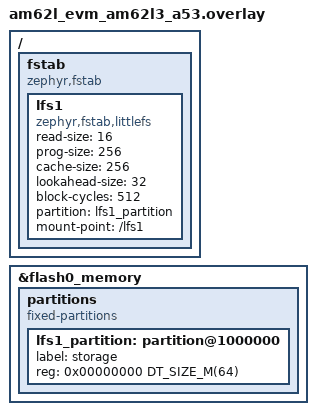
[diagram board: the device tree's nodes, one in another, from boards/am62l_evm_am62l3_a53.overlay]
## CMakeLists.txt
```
#
# Copyright (c) 2019 Peter Bigot Consulting, LLC
#
# SPDX-License-Identifier: Apache-2.0
#

cmake_minimum_required(VERSION 3.28.0)
find_package(Zephyr REQUIRED HINTS $ENV{ZEPHYR_BASE})
project(littlefs)

FILE(GLOB app_sources src/*.c)
target_sources(app PRIVATE ${app_sources})
```

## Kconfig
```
# Copyright (c) 2019 Peter Bigot Consulting, LLC
# SPDX-License-Identifier: Apache-2.0

mainmenu "littlefs sample"

config APP_WIPE_STORAGE
	bool "Option to clear the flash area before mounting"
	help
	  Use this to force an existing file system to be created.

choice
	prompt "Storage backend type used by the application"
	default APP_LITTLEFS_STORAGE_FLASH
	help
	  Specify the type of storage backend.

config APP_LITTLEFS_STORAGE_FLASH
	bool "Use flash memory backend"

config APP_LITTLEFS_STORAGE_BLK_SDMMC
	bool "Use block device (e.g. SD MMC) backend"

config APP_LITTLEFS_STORAGE_BLK_FTL
	bool "Use FTL (Flash Translation Layer) block device backend"
endchoice

source "Kconfig.zephyr"
```

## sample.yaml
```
sample:
  name: littlefs filesystem sample
common:
  tags:
    - filesystem
    - littefs
tests:
  sample.filesystem.littlefs:
    build_only: true
    platform_allow:
      - nrf52840dk/nrf52840
      - particle_xenon
      - disco_l475_iot1
      - mimxrt685_evk/mimxrt685s/cm33
      - mimxrt1060_evk/mimxrt1062/qspi
      - mimxrt1064_evk
      - qemu_x86
      - native_sim
      - mimxrt1160_evk/mimxrt1166/cm7
      - lpcxpresso55s69/lpc55s69/cpu0
      - mr_canhubk3
      - stm32f429i_disc1
      - stm32f746g_disco
      - stm32h747i_disco/stm32h747xx/m7
      - stm32h750b_dk
      - nrf54l15dk/nrf54l15/cpuapp
      - frdm_ke17z
      - frdm_ke17z512
      - s32z2xxdc2/s32z270/rtu0
      - s32z2xxdc2/s32z270/rtu1
      - s32z2xxdc2@D/s32z270/rtu0
      - s32z2xxdc2@D/s32z270/rtu1
      - s32k5xxcvb/s32k566/m7
      - s32k5xxcvb/s32k566/r52
    integration_platforms:
      - nrf52840dk/nrf52840
  sample.filesystem.littlefs.blk:
    build_only: true
    extra_args:
      - CONF_FILE=prj_blk.conf
    platform_allow:
      - rcar_h3ulcb/r8a77951/a57
      - rcar_salvator_xs
  sample.filesystem.littlefs.nrf52840dk_spi:
    build_only: true
    platform_allow: nrf52840dk/nrf52840
    extra_args:
      - EXTRA_CONF_FILE=boards/nrf52840dk_nrf52840_spi.conf
      - DTC_OVERLAY_FILE=boards/nrf52840dk_nrf52840_spi.overlay
  sample.filesystem.littlefs.nrf52840dk_qspi:
    build_only: true
    platform_allow: nrf52840dk/nrf52840
    extra_args:
      - EXTRA_CONF_FILE=boards/nrf52840dk_nrf52840_qspi.conf
      - DTC_OVERLAY_FILE=boards/nrf52840dk_nrf52840_qspi.overlay
  sample.filesystem.littlefs.stm32h747i_disco_m7_blk:
    build_only: true
    platform_allow: stm32h747i_disco/stm32h747xx/m7
    extra_args:
      - EXTRA_CONF_FILE=stm32_blk.conf
      - CONF_FILE=prj_blk.conf
    extra_configs:
      - CONFIG_SDMMC_STM32_HWFC=y
  sample.filesystem.littlefs.nucleo_h743zi_qspi:
    build_only: true
    platform_allow: nucleo_h743zi
    extra_args:
      - EXTRA_CONF_FILE=boards/nucleo_h743zi_qspi.conf
  sample.filesystem.littlefs.nucleo_h743zi_blk:
    build_only: true
    platform_allow: nucleo_h743zi
    extra_args:
      - EXTRA_CONF_FILE=boards/nucleo_h743zi_blk.conf
      - CONF_FILE=prj_blk.conf
  sample.filesystem.littlefs.stm32l562e_dk_ospi:
    build_only: true
    platform_allow: stm32l562e_dk
    extra_args:
      - EXTRA_CONF_FILE=boards/stm32l562e_dk_ospi.conf
  sample.filesystem.littlefs.stm32f746g_disco_blk:
    build_only: true
    platform_allow: stm32f746g_disco
    extra_args:
      - EXTRA_CONF_FILE=stm32_blk.conf
      - CONF_FILE=prj_blk.conf
    extra_configs:
      - CONFIG_SDMMC_STM32_HWFC=y
  sample.filesystem.littlefs.frdm_rw612_nand:
    build_only: true
    platform_allow: frdm_rw612
    extra_args:
      - EXTRA_CONF_FILE=boards/frdm_rw612_nand.conf
      - DTC_OVERLAY_FILE=boards/frdm_rw612_nand.overlay
```

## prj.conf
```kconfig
#
# Copyright (c) 2019 Peter Bigot Consulting, LLC
#
# SPDX-License-Identifier: Apache-2.0
#

# Optionally force the file system to be recreated
#CONFIG_APP_WIPE_STORAGE=y

# fs_dirent structures are big.
CONFIG_MAIN_STACK_SIZE=4096

# Let __ASSERT do its job
CONFIG_DEBUG=y

CONFIG_LOG=y
CONFIG_LOG_MODE_MINIMAL=y

CONFIG_FLASH=y
CONFIG_FLASH_MAP=y

CONFIG_FILE_SYSTEM=y
CONFIG_FILE_SYSTEM_LITTLEFS=y
```

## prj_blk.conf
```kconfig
#
# Copyright (c) 2022 Lukasz Majewski, DENX Software Engineering GmbH
#
# SPDX-License-Identifier: Apache-2.0
#

CONFIG_DISK_ACCESS=y
CONFIG_DISK_DRIVERS=y

CONFIG_DEBUG=y
CONFIG_LOG=y
CONFIG_LOG_MODE_MINIMAL=y

CONFIG_FILE_SYSTEM=y
CONFIG_FILE_SYSTEM_LITTLEFS=y

CONFIG_FS_LITTLEFS_BLK_DEV=y
CONFIG_FS_LITTLEFS_FMP_DEV=n
CONFIG_APP_LITTLEFS_STORAGE_BLK_SDMMC=y

CONFIG_NOCACHE_MEMORY=y
```

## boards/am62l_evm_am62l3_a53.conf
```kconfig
#
# SPDX-FileCopyrightText: 2026 Texas Instruments Incorporated
#
# SPDX-License-Identifier: Apache-2.0
#

CONFIG_MPU_ALLOW_FLASH_WRITE=y
```

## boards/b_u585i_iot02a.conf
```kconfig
#
# Copyright (c) 2023 OS Systems
#
# SPDX-License-Identifier: Apache-2.0
#

CONFIG_FS_LITTLEFS_FC_HEAP_SIZE=8192
```

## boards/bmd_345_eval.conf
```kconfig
#
# Copyright (c) 2021 Linumiz
#
# SPDX-License-Identifier: Apache-2.0

# Need this when storage is on flash
CONFIG_MPU_ALLOW_FLASH_WRITE=y

# Need this when storage is on MX25R64
CONFIG_NORDIC_QSPI_NOR_FLASH_LAYOUT_PAGE_SIZE=4096
```

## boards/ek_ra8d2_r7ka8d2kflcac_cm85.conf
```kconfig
# Copyright (c) 2026 Renesas Electronics Corporation
# SPDX-License-Identifier: Apache-2.0

CONFIG_HEAP_MEM_POOL_SIZE=2048
```

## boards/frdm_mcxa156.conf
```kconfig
# Copyright 2025 NXP
# SPDX-License-Identifier: Apache-2.0

CONFIG_FS_LITTLEFS_PROG_SIZE=128
CONFIG_FS_LITTLEFS_CACHE_SIZE=128
```

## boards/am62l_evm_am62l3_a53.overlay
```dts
/*
 * SPDX-FileCopyrightText: 2026 Texas Instruments Incorporated
 *
 * SPDX-License-Identifier: Apache-2.0
 */

/ {
	fstab {
		compatible = "zephyr,fstab";

		lfs1: lfs1 {
			compatible = "zephyr,fstab,littlefs";
			read-size = <16>;
			prog-size = <256>;
			cache-size = <256>;
			lookahead-size = <32>;
			block-cycles = <512>;
			partition = <&lfs1_partition>;
			mount-point = "/lfs1";
		};
	};
};

&flash0_memory {
	partitions {
		compatible = "fixed-partitions";
		#address-cells = <1>;
		#size-cells = <1>;

		lfs1_partition: partition@1000000 {
			label = "storage";
			reg = <0x00000000 DT_SIZE_M(64)>;
		};
	};
};
```

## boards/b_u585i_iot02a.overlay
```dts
/*
 * Copyright (c) 2023 OS Systems
 *
 * SPDX-License-Identifier: Apache-2.0
 */

/ {
	fstab {
		compatible = "zephyr,fstab";

		lfs1: lfs1 {
			compatible = "zephyr,fstab,littlefs";
			read-size = <256>;
			prog-size = <256>;
			cache-size = <4096>;
			lookahead-size = <256>;
			block-cycles = <512>;
			partition = <&lfs1_partition>;
			mount-point = "/lfs1";
			automount;
		};
	};
};

&mx25lm51245 {
	partitions {
		/delete-node/ partition;

		/* Use the whole flash for the filesystem. */
		lfs1_partition: partition@0 {
			reg = <0x00000000 DT_SIZE_M(64)>;
		};
	};
};
```

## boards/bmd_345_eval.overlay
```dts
/*
 * Copyright (c) 2021 Linumiz
 *
 * SPDX-License-Identifier: Apache-2.0
 */

/delete-node/ &storage_partition;

/ {
	fstab {
		compatible = "zephyr,fstab";

		lfs1: lfs1 {
			compatible = "zephyr,fstab,littlefs";
			mount-point = "/lfs1";
			partition = <&lfs1_part>;
			automount;
			read-size = <16>;
			prog-size = <16>;
			cache-size = <64>;
			lookahead-size = <32>;
			block-cycles = <512>;
		};
	};
};

&mx25r64 {
	partitions {
		compatible = "fixed-partitions";
		#address-cells = <1>;
		#size-cells = <1>;

		lfs1_part: partition@0 {
			label = "storage";
			reg = <0x00000000 0x00010000>;
		};
	};
};
```

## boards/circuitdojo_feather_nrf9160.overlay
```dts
/*
 * Copyright (c) 2020 Circuit Dojo LLC
 *
 * SPDX-License-Identifier: Apache-2.0
 */

/delete-node/ &storage_partition;

&w25q16jv {
	partitions {
		compatible = "fixed-partitions";
		#address-cells = <1>;
		#size-cells = <1>;

		littlefs_dev: partition@0 {
			reg = <0x00000000 0x00010000>;
			label = "storage";
		};
	};
};
```

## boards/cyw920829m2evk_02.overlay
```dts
/ {
	fstab {
		compatible = "zephyr,fstab";

		lfs1: lfs1 {
			compatible = "zephyr,fstab,littlefs";
			mount-point = "/lfs1";
			partition = <&storage_partition>;
			read-size = <16>;
			prog-size = <16>;
			cache-size = <64>;
			lookahead-size = <32>;
			block-cycles = <512>;
		};
	};
};
```

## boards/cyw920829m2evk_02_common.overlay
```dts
/*
 * SPDX-FileCopyrightText: <text>Copyright (c) 2026 Infineon Technologies AG,
 * or an affiliate of Infineon Technologies AG. All rights reserved.</text>
 *
 * SPDX-License-Identifier: Apache-2.0
 */

/ {
	fstab {
		compatible = "zephyr,fstab";

		lfs1: lfs1 {
			compatible = "zephyr,fstab,littlefs";
			mount-point = "/lfs1";
			partition = <&storage_partition>;
			read-size = <16>;
			prog-size = <16>;
			cache-size = <64>;
			lookahead-size = <32>;
			block-cycles = <512>;
		};
	};
};
```

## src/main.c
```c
/*
 * Copyright (c) 2022 Lukasz Majewski, DENX Software Engineering GmbH
 * Copyright (c) 2019 Peter Bigot Consulting, LLC
 *
 * SPDX-License-Identifier: Apache-2.0
 */

/* Sample which uses the filesystem API with littlefs */

#include <stdio.h>

#include <zephyr/kernel.h>
#include <zephyr/device.h>
#include <zephyr/fs/fs.h>
#include <zephyr/fs/littlefs.h>
#include <zephyr/logging/log.h>
#include <zephyr/storage/flash_map.h>

LOG_MODULE_REGISTER(main);

/* Matches LFS_NAME_MAX */
#define MAX_PATH_LEN 255
#define TEST_FILE_SIZE 547

static uint8_t file_test_pattern[TEST_FILE_SIZE];
static int lsdir(const char *path)
{
	int res;
	struct fs_dir_t dirp;
	static struct fs_dirent entry;

	fs_dir_t_init(&dirp);

	/* Verify fs_opendir() */
	res = fs_opendir(&dirp, path);
	if (res) {
		LOG_ERROR("Error opening dir %s [%d]\n", path, res);
		return res;
	}

	LOG_PRINTK("\nListing dir %s ...\n", path);
	for (;;) {
		/* Verify fs_readdir() */
		res = fs_readdir(&dirp, &entry);

		/* entry.name[0] == 0 means end-of-dir */
		if (res || entry.name[0] == 0) {
			if (res < 0) {
				LOG_ERROR("Error reading dir [%d]\n", res);
			}
			break;
		}

		if (entry.type == FS_DIR_ENTRY_DIR) {
			LOG_PRINTK("[DIR ] %s\n", entry.name);
		} else {
			LOG_PRINTK("[FILE] %s (size = %zu)\n",
				   entry.name, entry.size);
		}
	}

	/* Verify fs_closedir() */
	fs_closedir(&dirp);

	return res;
}

static int littlefs_increase_infile_value(char *fname)
{
	uint8_t boot_count = 0;
	struct fs_file_t file;
	int rc, ret;

	fs_file_t_init(&file);
	rc = fs_open(&file, fname, FS_O_CREATE | FS_O_RDWR);
	if (rc < 0) {
		LOG_ERROR("FAIL: open %s: %d", fname, rc);
		return rc;
	}

	rc = fs_read(&file, &boot_count, sizeof(boot_count));
	if (rc < 0) {
		LOG_ERROR("FAIL: read %s: [rd:%d]", fname, rc);
		goto out;
	}
	LOG_PRINTK("%s read count:%u (bytes: %d)\n", fname, boot_count, rc);

	rc = fs_seek(&file, 0, FS_SEEK_SET);
	if (rc < 0) {
		LOG_ERROR("FAIL: seek %s: %d", fname, rc);
		goto out;
	}

	boot_count += 1;
	rc = fs_write(&file, &boot_count, sizeof(boot_count));
	if (rc < 0) {
		LOG_ERROR("FAIL: write %s: %d", fname, rc);
		goto out;
	}

	LOG_PRINTK("%s write new boot count %u: [wr:%d]\n", fname,
		   boot_count, rc);

 out:
	ret = fs_close(&file);
	if (ret < 0) {
		LOG_ERROR("FAIL: close %s: %d", fname, ret);
		return ret;
	}

	return (rc < 0 ? rc : 0);
}

static void incr_pattern(uint8_t *p, uint16_t size, uint8_t inc)
{
	uint8_t fill = 0x55;

	if (p[0] % 2 == 0) {
		fill = 0xAA;
	}

	for (int i = 0; i < (size - 1); i++) {
		if (i % 8 == 0) {
			p[i] += inc;
		} else {
			p[i] = fill;
		}
	}

	p[size - 1] += inc;
}

static void init_pattern(uint8_t *p, uint16_t size)
{
	uint8_t v = 0x1;

	memset(p, 0x55, size);

	for (int i = 0; i < size; i += 8) {
		p[i] = v++;
	}

	p[size - 1] = 0xAA;
}

static void print_pattern(uint8_t *p, uint16_t size)
{
	int i, j = size / 16, k;

	for (k = 0, i = 0; k < j; i += 16, k++) {
		LOG_PRINTK("%02x %02x %02x %02x %02x %02x %02x %02x ",
			   p[i], p[i+1], p[i+2], p[i+3],
			   p[i+4], p[i+5], p[i+6], p[i+7]);
		LOG_PRINTK("%02x %02x %02x %02x %02x %02x %02x %02x\n",
			   p[i+8], p[i+9], p[i+10], p[i+11],
			   p[i+12], p[i+13], p[i+14], p[i+15]);

		/* Mark 512B (sector) chunks of the test file */
		if ((k + 1) % 32 == 0) {
			LOG_PRINTK("\n");
		}
	}

	for (; i < size; i++) {
		LOG_PRINTK("%02x ", p[i]);
	}

	LOG_PRINTK("\n");
}

static int littlefs_binary_file_adj(char *fname)
{
	struct fs_dirent dirent;
	struct fs_file_t file;
	int rc, ret;

	/*
	 * Uncomment below line to force re-creation of the test pattern
	 * file on the littlefs FS.
	 */
	/* fs_unlink(fname); */
	fs_file_t_init(&file);

	rc = fs_open(&file, fname, FS_O_CREATE | FS_O_RDWR);
	if (rc < 0) {
		LOG_ERROR("FAIL: open %s: %d", fname, rc);
		return rc;
	}

	rc = fs_stat(fname, &dirent);
	if (rc < 0) {
		LOG_ERROR("FAIL: stat %s: %d", fname, rc);
		goto out;
	}

	/* Check if the file exists - if not just write the pattern */
	if (rc == 0 && dirent.type == FS_DIR_ENTRY_FILE && dirent.size == 0) {
		LOG_INF("Test file: %s not found, create one!",
			fname);
		init_pattern(file_test_pattern, sizeof(file_test_pattern));
	} else {
		rc = fs_read(&file, file_test_pattern,
			     sizeof(file_test_pattern));
		if (rc < 0) {
			LOG_ERROR("FAIL: read %s: [rd:%d]", fname, rc);
			goto out;
		}
		incr_pattern(file_test_pattern, sizeof(file_test_pattern), 0x1);
	}

	LOG_PRINTK("------ FILE: %s ------\n", fname);
	print_pattern(file_test_pattern, sizeof(file_test_pattern));

	rc = fs_seek(&file, 0, FS_SEEK_SET);
	if (rc < 0) {
		LOG_ERROR("FAIL: seek %s: %d", fname, rc);
		goto out;
	}

	rc = fs_write(&file, file_test_pattern, sizeof(file_test_pattern));
	if (rc < 0) {
		LOG_ERROR("FAIL: write %s: %d", fname, rc);
	}

 out:
	ret = fs_close(&file);
	if (ret < 0) {
		LOG_ERROR("FAIL: close %s: %d", fname, ret);
		return ret;
	}

	return (rc < 0 ? rc : 0);
}

#ifdef CONFIG_APP_LITTLEFS_STORAGE_FLASH
static int littlefs_flash_erase(unsigned int id)
{
	const struct flash_area *pfa;
	int rc;

	rc = flash_area_open(id, &pfa);
	if (rc < 0) {
		LOG_ERROR("FAIL: unable to find flash area %u: %d\n", id, rc);
		return rc;
	}

	LOG_PRINTK("Area %u at 0x%x on %s for %u bytes\n",
		   id, (unsigned int)pfa->fa_off, pfa->fa_dev->name,
		   (unsigned int)pfa->fa_size);

	/* Optional wipe flash contents */
	if (IS_ENABLED(CONFIG_APP_WIPE_STORAGE)) {
		rc = flash_area_flatten(pfa, 0, pfa->fa_size);
		LOG_ERROR("Erasing flash area ... %d", rc);
	}

	flash_area_close(pfa);
	return rc;
}
#define PARTITION_NODE DT_NODELABEL(lfs1)

#if DT_NODE_EXISTS(PARTITION_NODE)
FS_FSTAB_DECLARE_ENTRY(PARTITION_NODE);
#else /* PARTITION_NODE */
FS_LITTLEFS_DECLARE_DEFAULT_CONFIG(storage);
static struct fs_mount_t lfs_storage_mnt = {
	.type = FS_LITTLEFS,
	.fs_data = &storage,
	.storage_dev = (void *)PARTITION_ID(storage_partition),
	.mnt_point = "/lfs",
};
#endif /* PARTITION_NODE */

	struct fs_mount_t *mountpoint =
#if DT_NODE_EXISTS(PARTITION_NODE)
		&FS_FSTAB_ENTRY(PARTITION_NODE)
#else
		&lfs_storage_mnt
#endif
		;

static int littlefs_mount(struct fs_mount_t *mp)
{
	int rc;

	rc = littlefs_flash_erase((uintptr_t)mp->storage_dev);
	if (rc < 0) {
		return rc;
	}

	/* Do not mount if auto-mount has been enabled */
#if !DT_NODE_EXISTS(PARTITION_NODE) ||						\
	!(FSTAB_ENTRY_DT_MOUNT_FLAGS(PARTITION_NODE) & FS_MOUNT_FLAG_AUTOMOUNT)
	rc = fs_mount(mp);
	if (rc < 0) {
		LOG_PRINTK("FAIL: mount id %" PRIuPTR " at %s: %d\n",
		       (uintptr_t)mp->storage_dev, mp->mnt_point, rc);
		return rc;
	}
	LOG_PRINTK("%s mount: %d\n", mp->mnt_point, rc);
#else
	LOG_PRINTK("%s automounted\n", mp->mnt_point);
#endif

	return 0;
}
#endif /* CONFIG_APP_LITTLEFS_STORAGE_FLASH */

#ifdef CONFIG_APP_LITTLEFS_STORAGE_BLK_SDMMC
#if defined(CONFIG_DISK_DRIVER_SDMMC)
#define DISK_NAME "SD"
#elif defined(CONFIG_DISK_DRIVER_MMC)
#define DISK_NAME "SD2"
#else
#error "No disk device defined, is your board supported?"
#endif
#endif /* CONFIG_APP_LITTLEFS_STORAGE_BLK_SDMMC */

#ifdef CONFIG_APP_LITTLEFS_STORAGE_BLK_FTL
#define DISK_NAME "NAND"
#endif /* CONFIG_APP_LITTLEFS_STORAGE_BLK_FTL */

#if defined(CONFIG_APP_LITTLEFS_STORAGE_BLK_SDMMC) || \
	defined(CONFIG_APP_LITTLEFS_STORAGE_BLK_FTL)

struct fs_littlefs lfsfs;
static struct fs_mount_t __mp = {
	.type = FS_LITTLEFS,
	.fs_data = &lfsfs,
	.flags = FS_MOUNT_FLAG_USE_DISK_ACCESS,
};
struct fs_mount_t *mountpoint = &__mp;

static int littlefs_mount(struct fs_mount_t *mp)
{
	static const char *disk_mount_pt = "/"DISK_NAME":";
	static const char *disk_pdrv = DISK_NAME;

	mp->storage_dev = (void *)disk_pdrv;
	mp->mnt_point = disk_mount_pt;

	return fs_mount(mp);
}
#endif /* CONFIG_APP_LITTLEFS_STORAGE_BLK_SDMMC || CONFIG_APP_LITTLEFS_STORAGE_BLK_FTL */

int main(void)
{
	char fname1[MAX_PATH_LEN];
	char fname2[MAX_PATH_LEN];
	struct fs_statvfs sbuf;
	int rc;

	LOG_PRINTK("Sample program to r/w files on littlefs\n");

	rc = littlefs_mount(mountpoint);
	if (rc < 0) {
		return 0;
	}

	snprintf(fname1, sizeof(fname1), "%s/boot_count", mountpoint->mnt_point);
	snprintf(fname2, sizeof(fname2), "%s/pattern.bin", mountpoint->mnt_point);

	rc = fs_statvfs(mountpoint->mnt_point, &sbuf);
	if (rc < 0) {
		LOG_PRINTK("FAIL: statvfs: %d\n", rc);
		goto out;
	}

	LOG_PRINTK("%s: bsize = %lu ; frsize = %lu ;"
		   " blocks = %lu ; bfree = %lu\n",
		   mountpoint->mnt_point,
		   sbuf.f_bsize, sbuf.f_frsize,
		   sbuf.f_blocks, sbuf.f_bfree);

	rc = lsdir(mountpoint->mnt_point);
	if (rc < 0) {
		LOG_PRINTK("FAIL: lsdir %s: %d\n", mountpoint->mnt_point, rc);
		goto out;
	}

	rc = littlefs_increase_infile_value(fname1);
	if (rc) {
		goto out;
	}

	rc = littlefs_binary_file_adj(fname2);
	if (rc) {
		goto out;
	}

out:
	rc = fs_unmount(mountpoint);
	LOG_PRINTK("%s unmount: %d\n", mountpoint->mnt_point, rc);
	return 0;
}
```
